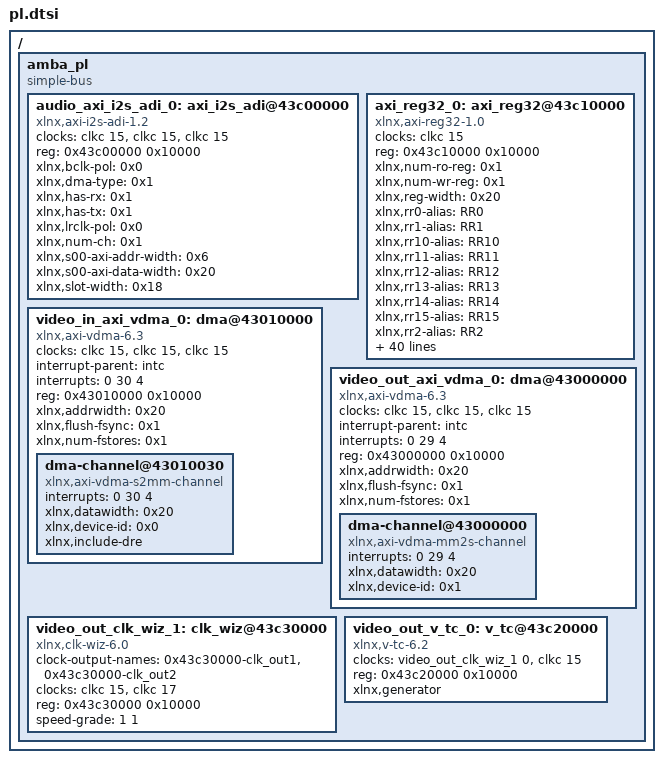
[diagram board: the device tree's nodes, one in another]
/*
 * CAUTION: This file is automatically generated by Xilinx.
 * Version: XSCT 2021.2
 * Today is: Sun Mar  6 03:19:21 2022
 */


/ {
	amba_pl: amba_pl {
		#address-cells = <1>;
		#size-cells = <1>;
		compatible = "simple-bus";
		ranges ;
		audio_axi_i2s_adi_0: axi_i2s_adi@43c00000 {
			/* This is a place holder node for a custom IP, user may need to update the entries */
			clock-names = "DMA_REQ_TX_ACLK", "DMA_REQ_RX_ACLK", "s00_axi_aclk";
			clocks = <&clkc 15>, <&clkc 15>, <&clkc 15>;
			compatible = "xlnx,axi-i2s-adi-1.2";
			reg = <0x43c00000 0x10000>;
			xlnx,bclk-pol = <0x0>;
			xlnx,dma-type = <0x1>;
			xlnx,has-rx = <0x1>;
			xlnx,has-tx = <0x1>;
			xlnx,lrclk-pol = <0x0>;
			xlnx,num-ch = <0x1>;
			xlnx,s00-axi-addr-width = <0x6>;
			xlnx,s00-axi-data-width = <0x20>;
			xlnx,slot-width = <0x18>;
		};
		axi_reg32_0: axi_reg32@43c10000 {
			/* This is a place holder node for a custom IP, user may need to update the entries */
			clock-names = "s_axi_aclk";
			clocks = <&clkc 15>;
			compatible = "xlnx,axi-reg32-1.0";
			reg = <0x43c10000 0x10000>;
			xlnx,num-ro-reg = <0x1>;
			xlnx,num-wr-reg = <0x1>;
			xlnx,reg-width = <0x20>;
			xlnx,rr0-alias = "RR0";
			xlnx,rr1-alias = "RR1";
			xlnx,rr10-alias = "RR10";
			xlnx,rr11-alias = "RR11";
			xlnx,rr12-alias = "RR12";
			xlnx,rr13-alias = "RR13";
			xlnx,rr14-alias = "RR14";
			xlnx,rr15-alias = "RR15";
			xlnx,rr2-alias = "RR2";
			xlnx,rr3-alias = "RR3";
			xlnx,rr4-alias = "RR4";
			xlnx,rr5-alias = "RR5";
			xlnx,rr6-alias = "RR6";
			xlnx,rr7-alias = "RR7";
			xlnx,rr8-alias = "RR8";
			xlnx,rr9-alias = "RR9";
			xlnx,wr-readable = "true";
			xlnx,wr0-alias = "WR0";
			xlnx,wr0-default = <0x0>;
			xlnx,wr1-alias = "WR1";
			xlnx,wr1-default = <0x0>;
			xlnx,wr10-alias = "WR10";
			xlnx,wr10-default = <0x0>;
			xlnx,wr11-alias = "WR11";
			xlnx,wr11-default = <0x0>;
			xlnx,wr12-alias = "WR12";
			xlnx,wr12-default = <0x0>;
			xlnx,wr13-alias = "WR13";
			xlnx,wr13-default = <0x0>;
			xlnx,wr14-alias = "WR14";
			xlnx,wr14-default = <0x0>;
			xlnx,wr15-alias = "WR15";
			xlnx,wr15-default = <0x0>;
			xlnx,wr2-alias = "WR2";
			xlnx,wr2-default = <0x0>;
			xlnx,wr3-alias = "WR3";
			xlnx,wr3-default = <0x0>;
			xlnx,wr4-alias = "WR4";
			xlnx,wr4-default = <0x0>;
			xlnx,wr5-alias = "WR5";
			xlnx,wr5-default = <0x0>;
			xlnx,wr6-alias = "WR6";
			xlnx,wr6-default = <0x0>;
			xlnx,wr7-alias = "WR7";
			xlnx,wr7-default = <0x0>;
			xlnx,wr8-alias = "WR8";
			xlnx,wr8-default = <0x0>;
			xlnx,wr9-alias = "WR9";
			xlnx,wr9-default = <0x0>;
		};
		video_in_axi_vdma_0: dma@43010000 {
			#dma-cells = <1>;
			clock-names = "s_axi_lite_aclk", "m_axi_s2mm_aclk", "s_axis_s2mm_aclk";
			clocks = <&clkc 15>, <&clkc 15>, <&clkc 15>;
			compatible = "xlnx,axi-vdma-6.3", "xlnx,axi-vdma-1.00.a";
			interrupt-names = "s2mm_introut";
			interrupt-parent = <&intc>;
			interrupts = <0 30 4>;
			reg = <0x43010000 0x10000>;
			xlnx,addrwidth = <0x20>;
			xlnx,flush-fsync = <0x1>;
			xlnx,num-fstores = <0x1>;
			dma-channel@43010030 {
				compatible = "xlnx,axi-vdma-s2mm-channel";
				interrupts = <0 30 4>;
				xlnx,datawidth = <0x20>;
				xlnx,device-id = <0x0>;
				xlnx,include-dre ;
			};
		};
		video_out_axi_vdma_0: dma@43000000 {
			#dma-cells = <1>;
			clock-names = "s_axi_lite_aclk", "m_axi_mm2s_aclk", "m_axis_mm2s_aclk";
			clocks = <&clkc 15>, <&clkc 15>, <&clkc 15>;
			compatible = "xlnx,axi-vdma-6.3", "xlnx,axi-vdma-1.00.a";
			interrupt-names = "mm2s_introut";
			interrupt-parent = <&intc>;
			interrupts = <0 29 4>;
			reg = <0x43000000 0x10000>;
			xlnx,addrwidth = <0x20>;
			xlnx,flush-fsync = <0x1>;
			xlnx,num-fstores = <0x1>;
			dma-channel@43000000 {
				compatible = "xlnx,axi-vdma-mm2s-channel";
				interrupts = <0 29 4>;
				xlnx,datawidth = <0x20>;
				xlnx,device-id = <0x1>;
			};
		};
		video_out_clk_wiz_1: clk_wiz@43c30000 {
			#clock-cells = <1>;
			clock-names = "s_axi_aclk", "clk_in1";
			clock-output-names = "0x43c30000-clk_out1", "0x43c30000-clk_out2";
			clocks = <&clkc 15>, <&clkc 17>;
			compatible = "xlnx,clk-wiz-6.0", "xlnx,clocking-wizard";
			reg = <0x43c30000 0x10000>;
			speed-grade = <1 1>;
		};
		video_out_v_tc_0: v_tc@43c20000 {
			clock-names = "clk", "s_axi_aclk";
			clocks = <&video_out_clk_wiz_1 0>, <&clkc 15>;
			compatible = "xlnx,v-tc-6.2", "xlnx,v-tc-6.1";
			reg = <0x43c20000 0x10000>;
			xlnx,generator ;
		};
	};
};
